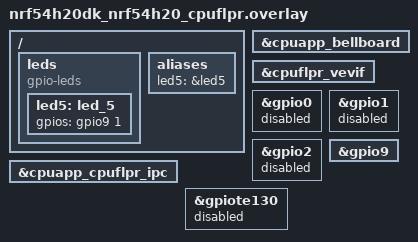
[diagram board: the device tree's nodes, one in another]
/*
 * Copyright (c) 2024 Nordic Semiconductor ASA
 *
 * SPDX-License-Identifier: LicenseRef-Nordic-5-Clause
 */

&cpuapp_bellboard {
	status = "okay";
};

&cpuflpr_vevif {
	status = "okay";
};

ipc0: &cpuapp_cpuflpr_ipc {
	status = "okay";
};

&gpio0 {
	status = "disabled";
};

&gpio1 {
	status = "disabled";
};

&gpio2 {
	status = "disabled";
};

&gpio9 {
	status = "okay";
};

&gpiote130 {
	status = "disabled";
	/delete-property/gpiote-instance;
};

/ {
	leds {
 		compatible = "gpio-leds";
 
 		led5: led_5 {
 			gpios = <&gpio9 1 GPIO_ACTIVE_HIGH>;
		};
 	};

	aliases {
		led5 = &led5;
	};
};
